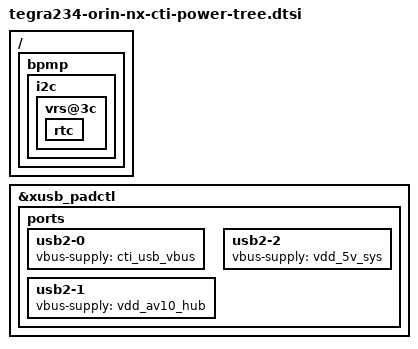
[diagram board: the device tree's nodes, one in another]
/*
 * Copyright (c) 2022, Connect Tech Inc.  All rights reserved.
 *
 * This program is free software; you can redistribute it and/or modify it
 * under the terms and conditions of the GNU General Public License,
 * version 2, as published by the Free Software Foundation.
 *
 * This program is distributed in the hope it will be useful, but WITHOUT
 * ANY WARRANTY; without even the implied warranty of MERCHANTABILITY or
 * FITNESS FOR A PARTICULAR PURPOSE.  See the GNU General Public License for
 * more details.
 *
 * You should have received a copy of the GNU General Public License
 * along with this program.  If not, see <http://www.gnu.org/licenses/>.
 */


#include "tegra234-orin-nx-cti-regulator.dtsi"

//defualt regulators for nx boards defined here

/{
    bpmp {
        i2c {
            vrs@3c {
                //Power Sequence RTC
                rtc {
                    status = "okay";
                };
            };
        };
    };
};

&xusb_padctl{
    
    ports {
        usb2-0 {
            vbus-supply = <&cti_usb_vbus>;
        };
        usb2-1 {
            vbus-supply = <&vdd_av10_hub>;
        };
        usb2-2 {
            vbus-supply = <&vdd_5v_sys>;
        };
    };
};
